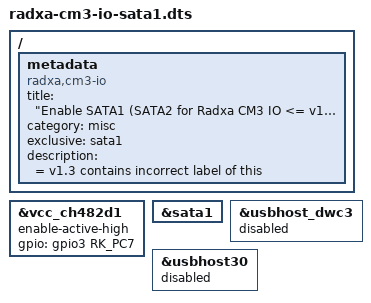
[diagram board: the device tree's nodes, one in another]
/dts-v1/;
/plugin/;

#include <dt-bindings/gpio/gpio.h>
#include <dt-bindings/pinctrl/rockchip.h>

/ {
	metadata {
		title = "Enable SATA1 (SATA2 for Radxa CM3 IO <= v1.3) and disable USB 3.0";
		compatible = "radxa,cm3-io";
		category = "misc";
		exclusive = "sata1";
		description = "Enable SATA1.\nWhen SATA1 is enabled, USB3.0 cannot be enabled on the same pin mux.\nRadxa CM3 IO  <= v1.3 contains incorrect label of this port.";
	};

	fragment@0 {
		target = <&vcc_ch482d1>;
		__overlay__ {
			enable-active-high;
			gpio = <&gpio3 RK_PC7 GPIO_ACTIVE_HIGH>;
			status = "okay";
		};
	};

	fragment@1 {
		target = <&sata1>;
		__overlay__ {
			status = "okay";
		};
	};

	fragment@2 {
		target = <&usbhost_dwc3>;

		__overlay__ {
			status = "disabled";
		};
	};

	fragment@3 {
		target = <&usbhost30>;

		__overlay__ {
			status = "disabled";
		};
	};

};
